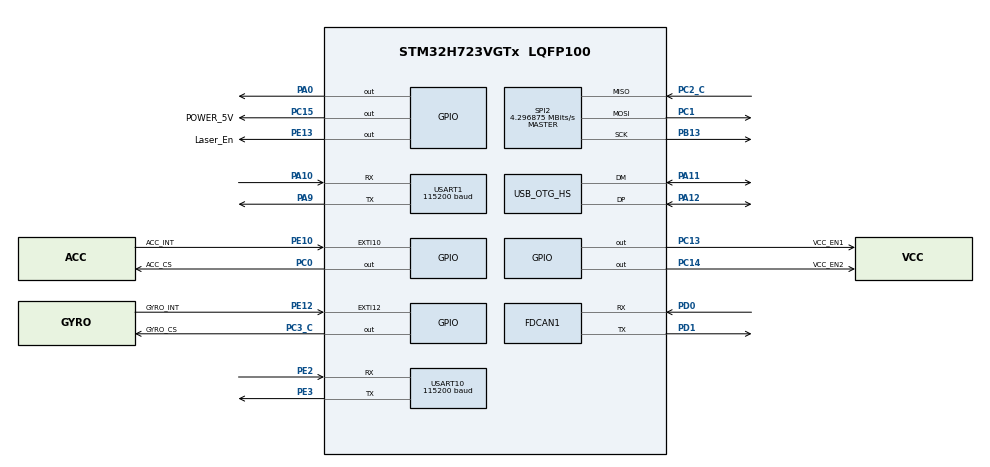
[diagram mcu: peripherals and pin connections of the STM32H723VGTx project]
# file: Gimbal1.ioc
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CORTEX_M7.AccessPermission-Cortex_Memory_Protection_Unit_Region0_Settings=MPU_REGION_FULL_ACCESS
CORTEX_M7.BaseAddress-Cortex_Memory_Protection_Unit_Region0_Settings=0x24000000
CORTEX_M7.CPU_DCache=Enabled
CORTEX_M7.CPU_ICache=Enabled
CORTEX_M7.Enable-Cortex_Memory_Protection_Unit_Region0_Settings=MPU_REGION_ENABLE
CORTEX_M7.Enable-Cortex_Memory_Protection_Unit_Region1_Settings=__NULL
CORTEX_M7.IsBufferable-Cortex_Memory_Protection_Unit_Region0_Settings=MPU_ACCESS_BUFFERABLE
CORTEX_M7.IsCacheable-Cortex_Memory_Protection_Unit_Region0_Settings=MPU_ACCESS_CACHEABLE
CORTEX_M7.MPU_Control=MPU_HFNMI_PRIVDEF
CORTEX_M7.Size-Cortex_Memory_Protection_Unit_Region0_Settings=MPU_REGION_SIZE_512KB
CORTEX_M7.TypeExtField-Cortex_Memory_Protection_Unit_Region0_Settings=MPU_TEX_LEVEL1
Dma.Request0=SPI2_RX
Dma.Request1=SPI2_TX
Dma.Request2=USART1_RX
Dma.Request3=USART1_TX
Dma.SPI2_RX.0.Direction=DMA_PERIPH_TO_MEMORY
Dma.SPI2_RX.0.EventEnable=DISABLE
Dma.SPI2_RX.0.FIFOMode=DMA_FIFOMODE_DISABLE
Dma.SPI2_RX.0.Instance=DMA1_Stream0
Dma.SPI2_RX.0.MemDataAlignment=DMA_MDATAALIGN_BYTE
Dma.SPI2_RX.0.MemInc=DMA_MINC_ENABLE
Dma.SPI2_RX.0.Mode=DMA_NORMAL
Dma.SPI2_RX.0.PeriphDataAlignment=DMA_PDATAALIGN_BYTE
Dma.SPI2_RX.0.PeriphInc=DMA_PINC_DISABLE
Dma.SPI2_RX.0.Polarity=HAL_DMAMUX_REQ_GEN_RISING
Dma.SPI2_RX.0.Priority=DMA_PRIORITY_VERY_HIGH
Dma.SPI2_RX.0.RequestNumber=1
Dma.SPI2_RX.0.SignalID=NONE
Dma.SPI2_RX.0.SyncEnable=DISABLE
Dma.SPI2_RX.0.SyncPolarity=HAL_DMAMUX_SYNC_NO_EVENT
Dma.SPI2_RX.0.SyncRequestNumber=1
Dma.SPI2_RX.0.SyncSignalID=NONE
Dma.SPI2_TX.1.Direction=DMA_MEMORY_TO_PERIPH
Dma.SPI2_TX.1.EventEnable=DISABLE
Dma.SPI2_TX.1.FIFOMode=DMA_FIFOMODE_DISABLE
Dma.SPI2_TX.1.Instance=DMA1_Stream1
Dma.SPI2_TX.1.MemDataAlignment=DMA_MDATAALIGN_BYTE
Dma.SPI2_TX.1.MemInc=DMA_MINC_ENABLE
Dma.SPI2_TX.1.Mode=DMA_NORMAL
Dma.SPI2_TX.1.PeriphDataAlignment=DMA_PDATAALIGN_BYTE
Dma.SPI2_TX.1.PeriphInc=DMA_PINC_DISABLE
Dma.SPI2_TX.1.Polarity=HAL_DMAMUX_REQ_GEN_RISING
Dma.SPI2_TX.1.Priority=DMA_PRIORITY_HIGH
Dma.SPI2_TX.1.RequestNumber=1
Dma.SPI2_TX.1.SignalID=NONE
Dma.SPI2_TX.1.SyncEnable=DISABLE
Dma.SPI2_TX.1.SyncPolarity=HAL_DMAMUX_SYNC_NO_EVENT
Dma.SPI2_TX.1.SyncRequestNumber=1
Dma.SPI2_TX.1.SyncSignalID=NONE
Dma.USART1_RX.2.Direction=DMA_PERIPH_TO_MEMORY
Dma.USART1_RX.2.EventEnable=DISABLE
Dma.USART1_RX.2.FIFOMode=DMA_FIFOMODE_DISABLE
Dma.USART1_RX.2.Instance=DMA1_Stream2
Dma.USART1_RX.2.MemDataAlignment=DMA_MDATAALIGN_BYTE
Dma.USART1_RX.2.MemInc=DMA_MINC_ENABLE
Dma.USART1_RX.2.Mode=DMA_NORMAL
Dma.USART1_RX.2.PeriphDataAlignment=DMA_PDATAALIGN_BYTE
Dma.USART1_RX.2.PeriphInc=DMA_PINC_DISABLE
Dma.USART1_RX.2.Polarity=HAL_DMAMUX_REQ_GEN_RISING
Dma.USART1_RX.2.Priority=DMA_PRIORITY_MEDIUM
Dma.USART1_RX.2.RequestNumber=1
Dma.USART1_RX.2.SignalID=NONE
Dma.USART1_RX.2.SyncEnable=DISABLE
Dma.USART1_RX.2.SyncPolarity=HAL_DMAMUX_SYNC_NO_EVENT
Dma.USART1_RX.2.SyncRequestNumber=1
Dma.USART1_RX.2.SyncSignalID=NONE
Dma.USART1_TX.3.Direction=DMA_MEMORY_TO_PERIPH
Dma.USART1_TX.3.EventEnable=DISABLE
Dma.USART1_TX.3.FIFOMode=DMA_FIFOMODE_DISABLE
Dma.USART1_TX.3.Instance=DMA1_Stream3
Dma.USART1_TX.3.MemDataAlignment=DMA_MDATAALIGN_BYTE
Dma.USART1_TX.3.MemInc=DMA_MINC_ENABLE
Dma.USART1_TX.3.Mode=DMA_NORMAL
Dma.USART1_TX.3.PeriphDataAlignment=DMA_PDATAALIGN_BYTE
Dma.USART1_TX.3.PeriphInc=DMA_PINC_DISABLE
Dma.USART1_TX.3.Polarity=HAL_DMAMUX_REQ_GEN_RISING
Dma.USART1_TX.3.Priority=DMA_PRIORITY_LOW
Dma.USART1_TX.3.RequestNumber=1
Dma.USART1_TX.3.SignalID=NONE
Dma.USART1_TX.3.SyncEnable=DISABLE
Dma.USART1_TX.3.SyncPolarity=HAL_DMAMUX_SYNC_NO_EVENT
Dma.USART1_TX.3.SyncRequestNumber=1
Dma.USART1_TX.3.SyncSignalID=NONE
FDCAN1.CalculateBaudRateNominal=1000000
FDCAN1.CalculateTimeBitNominal=1000
FDCAN1.CalculateTimeQuantumNominal=71.42857142857143
FDCAN1.AutoRetransmission=ENABLE
FDCAN1.ClockCalibrationCCU=DISABLE
FDCAN1.ClockDividerCCU=FDCAN_CLOCK_DIV1
FDCAN1.DataPrescaler=3
FDCAN1.DataSyncJumpWidth=6
FDCAN1.DataTimeSeg1=7
FDCAN1.DataTimeSeg2=6
FDCAN1.NominalPrescaler=3
FDCAN1.NominalSyncJumpWidth=6
FDCAN1.NominalTimeSeg1=7
FDCAN1.NominalTimeSeg2=6
FDCAN1.RxFifo0ElmtsNbr=4
FDCAN1.StdFiltersNbr=1
FDCAN1.TxFifoQueueElmtsNbr=4
FREERTOS.MEMORY_ALLOCATION=1
FREERTOS.Tasks01=defaultTask,24,128,StartDefaultTask,Default,NULL,Static,defaultTaskBuffer,defaultTaskControlBlock;ReceiveTask,24,256,StartReceiveTask,As external,NULL,Static,myTask03Buffer,myTask03ControlBlock;GimbalTask,24,256,StartGimbalTask,As external,NULL,Static,myTask04Buffer,myTask04ControlBlock
Mcu.Family=STM32H7
Mcu.Name=STM32H723VGTx
Mcu.Package=LQFP100
NVIC.DMA1_Stream0_IRQn=true\:6\:0\:true\:false\:true\:true\:false\:true\:true
NVIC.DMA1_Stream1_IRQn=true\:6\:0\:true\:false\:true\:true\:false\:true\:true
NVIC.DMA1_Stream2_IRQn=true\:5\:0\:true\:false\:true\:true\:false\:true\:true
NVIC.DMA1_Stream3_IRQn=true\:5\:0\:true\:false\:true\:true\:false\:true\:true
NVIC.EXTI15_10_IRQn=true\:6\:0\:true\:false\:true\:true\:true\:true\:true
NVIC.FDCAN1_IT0_IRQn=true\:5\:0\:false\:false\:true\:true\:true\:true\:true
NVIC.OTG_HS_IRQn=true\:5\:0\:false\:false\:true\:true\:true\:true\:true
NVIC.PriorityGroup=NVIC_PRIORITYGROUP_4
NVIC.SPI2_IRQn=true\:6\:0\:true\:false\:true\:true\:false\:true\:true
NVIC.TIM1_UP_IRQn=true\:15\:0\:false\:false\:true\:false\:false\:true\:true
NVIC.TimeBase=TIM1_UP_IRQn
NVIC.TimeBaseIP=TIM1
NVIC.USART10_IRQn=true\:5\:0\:false\:false\:true\:true\:true\:true\:true
NVIC.USART1_IRQn=true\:5\:0\:true\:false\:true\:true\:true\:true\:true
PA0.GPIO_Speed=GPIO_SPEED_FREQ_VERY_HIGH
PA0.Signal=GPIO_Output
PA10.Mode=Asynchronous
PA10.Signal=USART1_RX
PA11.Mode=Device_Only_FS
PA11.Signal=USB_OTG_HS_DM
PA12.Mode=Device_Only_FS
PA12.Signal=USB_OTG_HS_DP
PA13(JTMS/SWDIO).Mode=Serial_Wire
PA13(JTMS/SWDIO).Signal=DEBUG_JTMS-SWDIO
PA14(JTCK/SWCLK).Mode=Serial_Wire
PA14(JTCK/SWCLK).Signal=DEBUG_JTCK-SWCLK
PA9.Mode=Asynchronous
PA9.Signal=USART1_TX
PB13.GPIO_Speed=GPIO_SPEED_FREQ_VERY_HIGH
PB13.Mode=Full_Duplex_Master
PB13.Signal=SPI2_SCK
PC0.GPIO_Label=ACC_CS
PC0.GPIO_Speed=GPIO_SPEED_FREQ_VERY_HIGH
PC0.PinState=GPIO_PIN_SET
PC0.Signal=GPIO_Output
PC1.GPIO_Speed=GPIO_SPEED_FREQ_VERY_HIGH
PC1.Mode=Full_Duplex_Master
PC1.Signal=SPI2_MOSI
PC13.GPIO_Label=VCC_EN1
PC13.GPIO_PuPd=GPIO_PULLUP
PC13.PinState=GPIO_PIN_SET
PC13.Signal=GPIO_Output
PC14-OSC32_IN.GPIO_Label=VCC_EN2
PC14-OSC32_IN.GPIO_PuPd=GPIO_PULLUP
PC14-OSC32_IN.PinState=GPIO_PIN_SET
PC14-OSC32_IN.Signal=GPIO_Output
PC15-OSC32_OUT.GPIO_Label=POWER_5V
PC15-OSC32_OUT.PinState=GPIO_PIN_SET
PC15-OSC32_OUT.Signal=GPIO_Output
PC2_C.GPIO_Speed=GPIO_SPEED_FREQ_VERY_HIGH
PC2_C.Mode=Full_Duplex_Master
PC2_C.Signal=SPI2_MISO
PC3_C.GPIO_Label=GYRO_CS
PC3_C.GPIO_Speed=GPIO_SPEED_FREQ_VERY_HIGH
PC3_C.PinState=GPIO_PIN_SET
PC3_C.Signal=GPIO_Output
PD0.GPIO_Speed=GPIO_SPEED_FREQ_VERY_HIGH
PD0.Mode=FDCAN_Activate
PD0.Signal=FDCAN1_RX
PD1.GPIO_Speed=GPIO_SPEED_FREQ_VERY_HIGH
PD1.Mode=FDCAN_Activate
PD1.Signal=FDCAN1_TX
PE10.GPIO_Label=ACC_INT
PE10.Signal=GPXTI10
PE12.GPIO_Label=GYRO_INT
PE12.Signal=GPXTI12
PE13.GPIO_Label=Laser_En
PE13.GPIO_PuPd=GPIO_PULLDOWN
PE13.PinState=GPIO_PIN_RESET
PE13.Signal=GPIO_Output
PE2.Mode=Asynchronous
PE2.Signal=USART10_RX
PE3.Mode=Asynchronous
PE3.Signal=USART10_TX
PH0-OSC_IN.Mode=HSE-External-Oscillator
PH0-OSC_IN.Signal=RCC_OSC_IN
PH1-OSC_OUT.Mode=HSE-External-Oscillator
PH1-OSC_OUT.Signal=RCC_OSC_OUT
ProjectManager.HeapSize=0x1000
ProjectManager.StackSize=0x2000
ProjectManager.TargetToolchain=CMake
RCC.ADCFreq_Value=42000000
RCC.APB1Freq_Value=137500000
RCC.APB2Freq_Value=137500000
RCC.APB3Freq_Value=137500000
RCC.APB4Freq_Value=137500000
RCC.CortexFreq_Value=550000000
RCC.D1PPRE=RCC_APB3_DIV2
RCC.D2PPRE1=RCC_APB1_DIV2
RCC.D2PPRE2=RCC_APB2_DIV2
RCC.D3PPRE=RCC_APB4_DIV2
RCC.DIVM1=3
RCC.DIVM2=2
RCC.DIVN1=68
RCC.DIVN2=28
RCC.DIVP1=1
RCC.DIVP2=8
RCC.DIVQ1=4
RCC.DIVQ2=8
RCC.FDCANCLockSelection=RCC_FDCANCLKSOURCE_PLL2
RCC.HCLKFreq_Value=275000000
RCC.HPRE=RCC_HCLK_DIV2
RCC.HSE_VALUE=24000000
RCC.PLL2FRACN=0
RCC.PLL3FRACN=0
RCC.PLLFRACN=6144
RCC.PLLSourceVirtual=RCC_PLLSOURCE_HSE
RCC.SYSCLKFreq_VALUE=550000000
RCC.SYSCLKSource=RCC_SYSCLKSOURCE_PLLCLK
RCC.USBCLockSelection=RCC_USBCLKSOURCE_HSI48
RCC.USBFreq_Value=48000000
SPI2.BaudRatePrescaler=SPI_BAUDRATEPRESCALER_32
SPI2.CLKPhase=SPI_PHASE_2EDGE
SPI2.CLKPolarity=SPI_POLARITY_HIGH
SPI2.CalculateBaudRate=4.296875 MBits/s
SPI2.DataSize=SPI_DATASIZE_8BIT
SPI2.Direction=SPI_DIRECTION_2LINES
SPI2.Mode=SPI_MODE_MASTER
SPI2.VirtualType=VM_MASTER
USART1.BaudRate=115200
USART1.VirtualMode-Asynchronous=VM_ASYNC
USART10.BaudRate=115200
USART10.VirtualMode=VM_ASYNC
USB_DEVICE.CLASS_NAME_HS=CDC
USB_DEVICE.VirtualMode=Cdc
USB_DEVICE.VirtualModeHS=Cdc_HS
USB_OTG_HS.VirtualMode-Device_Only_FS=Device_Only_FS
VP_FREERTOS_VS_CMSIS_V2.Mode=CMSIS_V2
VP_MEMORYMAP_VS_MEMORYMAP.Mode=CurAppReg
VP_SYS_VS_tim1.Mode=TIM1
VP_USB_DEVICE_VS_USB_DEVICE_CDC_HS.Mode=CDC_HS
board=custom

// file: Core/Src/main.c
/* USER CODE BEGIN Header */
/**
  ******************************************************************************
  * @file           : main.c
  * @brief          : Main program body
  ******************************************************************************
  * @attention
  *
  * Copyright (c) 2024 STMicroelectronics.
  * All rights reserved.
  *
  * This software is licensed under terms that can be found in the LICENSE file
  * in the root directory of this software component.
  * If no LICENSE file comes with this software, it is provided AS-IS.
  *
  ******************************************************************************
  */
/* USER CODE END Header */
#include "main.h"
#include "FreeRTOS.h"
#include "cmsis_os2.h"
#include "dma.h"
#include "fdcan.h"
#include "spi.h"
#include "usart.h"
#include "usb_device.h"
#include "gpio.h"

void SystemClock_Config(void);
static void MPU_Config(void);
void MX_FREERTOS_Init(void);

int main(void)
{

  /* MPU Configuration--------------------------------------------------------*/
  MPU_Config();

  /* Enable the CPU Cache */

  /* Enable I-Cache---------------------------------------------------------*/
  SCB_EnableICache();

  /* Enable D-Cache---------------------------------------------------------*/
  SCB_EnableDCache();

  /* MCU Configuration--------------------------------------------------------*/

  /* Reset of all peripherals, Initializes the Flash interface and the Systick. */
  HAL_Init();

  /* Configure the system clock */
  SystemClock_Config();

  /* USER CODE BEGIN SysInit */
  //DWT_Init(480);
  /* USER CODE END SysInit */

  /* Initialize all configured peripherals */
  MX_GPIO_Init();
  MX_DMA_Init();
  MX_SPI2_Init();
  MX_USART1_UART_Init();
  MX_FDCAN1_Init();
  MX_USART10_UART_Init();

  /* Init scheduler */
  osKernelInitialize();  /* Call init function for freertos objects (in cmsis_os2.c) */
  MX_FREERTOS_Init();

  /* Start scheduler */
  osKernelStart();

  /* We should never get here as control is now taken by the scheduler */

  /* Infinite loop */
  while (1)
  {

  }
}

void SystemClock_Config(void)
{
  RCC_OscInitTypeDef RCC_OscInitStruct = {0};
  RCC_ClkInitTypeDef RCC_ClkInitStruct = {0};

  /** Supply configuration update enable
  */
  HAL_PWREx_ConfigSupply(PWR_LDO_SUPPLY);

  /** Configure the main internal regulator output voltage
  */
  __HAL_PWR_VOLTAGESCALING_CONFIG(PWR_REGULATOR_VOLTAGE_SCALE0);

  while(!__HAL_PWR_GET_FLAG(PWR_FLAG_VOSRDY)) {}

  /** Initializes the RCC Oscillators according to the specified parameters
  * in the RCC_OscInitTypeDef structure.
  */
  RCC_OscInitStruct.OscillatorType = RCC_OSCILLATORTYPE_HSI48|RCC_OSCILLATORTYPE_HSE;
  RCC_OscInitStruct.HSEState = RCC_HSE_ON;
  RCC_OscInitStruct.HSI48State = RCC_HSI48_ON;
  RCC_OscInitStruct.PLL.PLLState = RCC_PLL_ON;
  RCC_OscInitStruct.PLL.PLLSource = RCC_PLLSOURCE_HSE;
  RCC_OscInitStruct.PLL.PLLM = 3;
  RCC_OscInitStruct.PLL.PLLN = 68;
  RCC_OscInitStruct.PLL.PLLP = 1;
  RCC_OscInitStruct.PLL.PLLQ = 4;
  RCC_OscInitStruct.PLL.PLLR = 2;
  RCC_OscInitStruct.PLL.PLLRGE = RCC_PLL1VCIRANGE_3;
  RCC_OscInitStruct.PLL.PLLVCOSEL = RCC_PLL1VCOWIDE;
  RCC_OscInitStruct.PLL.PLLFRACN = 6144;
  if (HAL_RCC_OscConfig(&RCC_OscInitStruct) != HAL_OK)
  {
    Error_Handler();
  }

  /** Initializes the CPU, AHB and APB buses clocks
  */
  RCC_ClkInitStruct.ClockType = RCC_CLOCKTYPE_HCLK|RCC_CLOCKTYPE_SYSCLK
                              |RCC_CLOCKTYPE_PCLK1|RCC_CLOCKTYPE_PCLK2
                              |RCC_CLOCKTYPE_D3PCLK1|RCC_CLOCKTYPE_D1PCLK1;
  RCC_ClkInitStruct.SYSCLKSource = RCC_SYSCLKSOURCE_PLLCLK;
  RCC_ClkInitStruct.SYSCLKDivider = RCC_SYSCLK_DIV1;
  RCC_ClkInitStruct.AHBCLKDivider = RCC_HCLK_DIV2;
  RCC_ClkInitStruct.APB3CLKDivider = RCC_APB3_DIV2;
  RCC_ClkInitStruct.APB1CLKDivider = RCC_APB1_DIV2;
  RCC_ClkInitStruct.APB2CLKDivider = RCC_APB2_DIV2;
  RCC_ClkInitStruct.APB4CLKDivider = RCC_APB4_DIV2;

  if (HAL_RCC_ClockConfig(&RCC_ClkInitStruct, FLASH_LATENCY_3) != HAL_OK)
  {
    Error_Handler();
  }
}

 /* MPU Configuration */

void MPU_Config(void)
{
  MPU_Region_InitTypeDef MPU_InitStruct = {0};

  /* Disables the MPU */
  HAL_MPU_Disable();

  /** Initializes and configures the Region and the memory to be protected
  */
  MPU_InitStruct.Enable = MPU_REGION_ENABLE;
  MPU_InitStruct.Number = MPU_REGION_NUMBER0;
  MPU_InitStruct.BaseAddress = 0x24000000;
  MPU_InitStruct.Size = MPU_REGION_SIZE_512KB;
  MPU_InitStruct.SubRegionDisable = 0x0;
  MPU_InitStruct.TypeExtField = MPU_TEX_LEVEL1;
  MPU_InitStruct.AccessPermission = MPU_REGION_FULL_ACCESS;
  MPU_InitStruct.DisableExec = MPU_INSTRUCTION_ACCESS_ENABLE;
  MPU_InitStruct.IsShareable = MPU_ACCESS_NOT_SHAREABLE;
  MPU_InitStruct.IsCacheable = MPU_ACCESS_CACHEABLE;
  MPU_InitStruct.IsBufferable = MPU_ACCESS_BUFFERABLE;

  HAL_MPU_ConfigRegion(&MPU_InitStruct);
  /* Enables the MPU */
  HAL_MPU_Enable(MPU_HFNMI_PRIVDEF);

}

void HAL_TIM_PeriodElapsedCallback(TIM_HandleTypeDef *htim)
{
  if (htim->Instance == TIM1)
  {
    HAL_IncTick();
  }
}

void Error_Handler(void)
{
  __disable_irq();
  while (1)
  {
  }
}

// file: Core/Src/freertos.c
/* USER CODE BEGIN Header */
/**
  ******************************************************************************
  * File Name          : freertos.c
  * Description        : Code for freertos applications
  ******************************************************************************
  * @attention
  *
  * Copyright (c) 2024 STMicroelectronics.
  * All rights reserved.
  *
  * This software is licensed under terms that can be found in the LICENSE file
  * in the root directory of this software component.
  * If no LICENSE file comes with this software, it is provided AS-IS.
  *
  ******************************************************************************
  */
/* USER CODE END Header */

#include "FreeRTOS.h"
#include "task.h"
#include "main.h"
#include "FreeRTOS.h"
#include "cmsis_os2.h"

/* USER CODE BEGIN Includes */
#include "task_public.h"
/* USER CODE END Includes */

typedef StaticTask_t osStaticThreadDef_t;

/* Definitions for defaultTask */
osThreadId_t defaultTaskHandle;
uint32_t defaultTaskBuffer[ 128 ];
osStaticThreadDef_t defaultTaskControlBlock;
const osThreadAttr_t defaultTask_attributes = {
  .name = "defaultTask",
  .cb_mem = &defaultTaskControlBlock,
  .cb_size = sizeof(defaultTaskControlBlock),
  .stack_mem = &defaultTaskBuffer[0],
  .stack_size = sizeof(defaultTaskBuffer),
  .priority = (osPriority_t) osPriorityNormal,
};
/* Definitions for ReceiveTask */
osThreadId_t ReceiveTaskHandle;
uint32_t myTask03Buffer[ 512 ];
osStaticThreadDef_t myTask03ControlBlock;
const osThreadAttr_t ReceiveTask_attributes = {
  .name = "ReceiveTask",
  .cb_mem = &myTask03ControlBlock,
  .cb_size = sizeof(myTask03ControlBlock),
  .stack_mem = &myTask03Buffer[0],
  .stack_size = sizeof(myTask03Buffer),
  .priority = (osPriority_t) osPriorityNormal,
};
/* Definitions for GimbalTask */
osThreadId_t GimbalTaskHandle;
uint32_t myTask04Buffer[ 512 ];
osStaticThreadDef_t myTask04ControlBlock;
const osThreadAttr_t GimbalTask_attributes = {
  .name = "GimbalTask",
  .cb_mem = &myTask04ControlBlock,
  .cb_size = sizeof(myTask04ControlBlock),
  .stack_mem = &myTask04Buffer[0],
  .stack_size = sizeof(myTask04Buffer),
  .priority = (osPriority_t) osPriorityNormal,
};

void StartDefaultTask(void *argument);
extern void StartReceiveTask(void *argument);
extern void StartGimbalTask(void *argument);

extern void MX_USB_DEVICE_Init(void);
void MX_FREERTOS_Init(void); /* (MISRA C 2004 rule 8.1) */

void MX_FREERTOS_Init(void) {

  /* Create the thread(s) */
  /* creation of defaultTask */
  defaultTaskHandle = osThreadNew(StartDefaultTask, NULL, &defaultTask_attributes);

  /* creation of ReceiveTask */
  ReceiveTaskHandle = osThreadNew(StartReceiveTask, NULL, &ReceiveTask_attributes);

  /* creation of GimbalTask */
  GimbalTaskHandle = osThreadNew(StartGimbalTask, NULL, &GimbalTask_attributes);

}

void StartDefaultTask(void *argument)
{
  /* init code for USB_DEVICE */
  MX_USB_DEVICE_Init();
  for(;;)
  {
    osDelay(1);
  }
}
